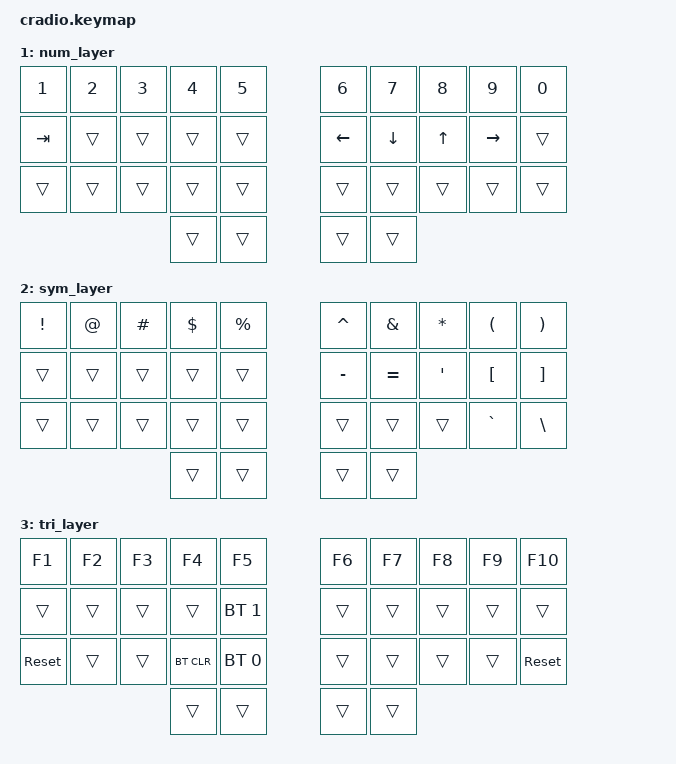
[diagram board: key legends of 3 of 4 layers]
// Copyright (c) 2022 The ZMK Contributors
// SPDX-License-Identifier: MIT

#include <behaviors.dtsi>
#include <dt-bindings/zmk/keys.h>
#include <dt-bindings/zmk/bt.h>

#define NUM 1
#define SYM 2

// Home row mods macro
#define HRML(k1,k2,k3,k4) &ht LALT k1  &ht LCTRL k2  &ht LGUI k3  &ht LSHFT k4
#define HRMR(k1,k2,k3,k4) &ht RSHFT k1  &ht RGUI k2  &ht RCTRL k3  &ht RALT k4

/ {
    behaviors { 
        ht: hold_tap {
            label = "hold_tap";
            compatible = "zmk,behavior-hold-tap";
            #binding-cells = <2>;
            flavor = "tap-preferred";
            tapping-term-ms = <220>;
            quick-tap-ms = <150>;
            require-prior-idle-ms = <100>;
            bindings = <&kp>, <&kp>;
        };
    };
    combos {
        compatible = "zmk,combos";
        combo_esc {
            key-positions = <0 1>;
            bindings = <&kp ESC>;
        };
    };

    conditional_layers {
        compatible = "zmk,conditional-layers";
        tri_layer {
            if-layers = <1 2>;
            then-layer = <3>;
        };
    };

    keymap {
        compatible = "zmk,keymap";
        default_layer {
            bindings = <
        //╭──────────┬──────────┬──────────┬──────────┬──────────╮   ╭──────────┬──────────┬──────────┬──────────┬──────────╮
        //│  Q       │  W       │  E       │  R       │  T       │   │  Y       │  U       │  I       │  O       │  P       │
            &kp Q      &kp W      &kp E      &kp R       &kp T         &kp Y      &kp U      &kp I      &kp O      &kp P
        //├──────────┼──────────┼──────────┼──────────┼──────────┤   ├──────────┼──────────┼──────────┼──────────┼──────────┤
        //│  A       │  S       │  D       │  F       │  G       │   │  H       │  J       │  K       │  L       │   ;      │
           HRML(A,         S,         D,         F)      &kp G         &kp H      HRMR(J,        K,         L,       SEMI)
        //├──────────┼──────────┼──────────┼──────────┼──────────┤   ├──────────┼──────────┼──────────┼──────────┼──────────┤
        //│  Z       │  X       │  C       │  V       │  B       │   │  N       │  M       │ , <      │ . >      │ / ?      │
            &kp Z      &kp X      &kp C      &kp V       &kp B         &kp N      &kp M      &kp COMMA  &kp DOT    &kp FSLH
        //╰──────────┴──────────┴──────────┼──────────┼──────────┤   ├──────────┼──────────┼──────────┴──────────┴──────────╯
                                           &lt NUM TAB  &kp SPACE      &kp BSPC  &lt SYM RET
        //                                 ╰──────────┴──────────╯   ╰──────────┴──────────╯
            >;
        };

        num_layer {
            bindings = <
        //╭──────────┬──────────┬──────────┬──────────┬──────────╮   ╭──────────┬──────────┬──────────┬──────────┬──────────╮
        //│    1     │    2     │    3     │    4     │    5     │   │    6     │    7     │    8     │    9     │     0    │
            &kp N1     &kp N2     &kp N3     &kp N4     &kp N5         &kp N6     &kp N7     &kp N8     &kp N9      &kp N0
        //├──────────┼──────────┼──────────┼──────────┼──────────┤   ├──────────┼──────────┼──────────┼──────────┼──────────┤
        //│          │          │          │          │          │   │          │          │          │          │          │
            &kp TAB    &trans     &trans     &trans     &trans         &kp LEFT   &kp DOWN   &kp UP     &kp RIGHT   &trans
        //├──────────┼──────────┼──────────┼──────────┼──────────┤   ├──────────┼──────────┼──────────┼──────────┼──────────┤
        //│          │          │          │          │          │   │          │          │          │          │          │
            &trans     &trans     &trans     &trans     &trans         &trans     &trans     &trans     &trans      &trans
        //╰──────────┴──────────┴──────────┼──────────┼──────────┤   ├──────────┼──────────┼──────────┴──────────┴──────────╯
                                             &trans     &trans         &trans     &trans
        //                                 ╰──────────┴──────────╯   ╰──────────┴──────────╯
            >;
        };

        sym_layer {
            bindings = <
        //╭──────────┬──────────┬──────────┬──────────┬──────────╮   ╭──────────┬──────────┬──────────┬──────────┬──────────╮
        //│    !     │    @     │   #      │    $     │    %     │   │     ^    │     &    │    *     │    (     │    )     │
            &kp EXCL   &kp AT     &kp HASH   &kp DLLR   &kp PRCNT      &kp CARET  &kp AMPS   &kp STAR   &kp LPAR   &kp RPAR    
        //├──────────┼──────────┼──────────┼──────────┼──────────┤   ├──────────┼──────────┼──────────┼──────────┼──────────┤
        //│          │          │          │          │          │   │     -    │    =     │    '     │    [     │    ]     │
            &trans     &trans     &trans     &trans     &trans         &kp MINUS  &kp EQUAL  &kp APOS   &kp LBKT   &kp RBKT
        //├──────────┼──────────┼──────────┼──────────┼──────────┤   ├──────────┼──────────┼──────────┼──────────┼──────────┤
        //│          │          │          │          │          │   │          │          │          │    ~     │    \     │
            &trans     &trans     &trans     &trans     &trans         &trans     &trans     &trans     &kp GRAVE  &kp BSLH
        //╰──────────┴──────────┴──────────┼──────────┼──────────┤   ├──────────┼──────────┼──────────┴──────────┴──────────╯
                                             &trans     &trans         &trans     &trans
        //                                 ╰──────────┴──────────╯   ╰──────────┴──────────╯
            >;
        };

        tri_layer {
            bindings = <
        //╭──────────┬──────────┬──────────┬──────────┬──────────╮   ╭──────────┬──────────┬──────────┬──────────┬──────────╮
        //│          │          │          │          │          │   │          │          │          │          │          │
            &kp F1     &kp F2     &kp F3     &kp F4     &kp F5         &kp F6     &kp F7     &kp F8     &kp F9     &kp F10  
        //├──────────┼──────────┼──────────┼──────────┼──────────┤   ├──────────┼──────────┼──────────┼──────────┼──────────┤
        //│          │          │          │          │          │   │          │          │          │          │          │
            &trans     &trans     &trans     &trans     &bt BT_SEL 1   &trans     &trans     &trans     &trans     &trans
        //├──────────┼──────────┼──────────┼──────────┼──────────┤   ├──────────┼──────────┼──────────┼──────────┼──────────┤
        //│          │          │          │          │          │   │          │          │          │          │          │
            &sys_reset &trans     &trans     &bt BT_CLR &bt BT_SEL 0   &trans     &trans     &trans     &trans     &sys_reset
        //╰──────────┴──────────┴──────────┼─────────-┼──────────┤   ├──────────┼──────────┼──────────┴──────────┴──────────╯
                                             &trans     &trans         &trans     &trans
        //                                 ╰──────────┴──────────╯   ╰──────────┴──────────╯
            >;
        };
    };
};
